AUTOSAR XML (schema 00044)
package /ComponentTypes
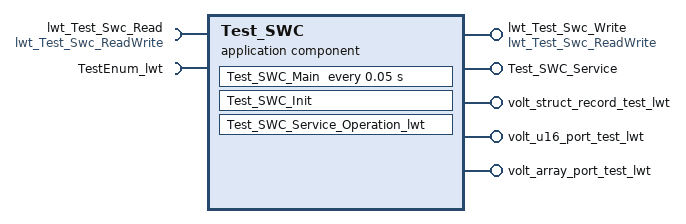
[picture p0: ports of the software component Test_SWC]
  application sw component type Test_SWC
    require port lwt_Test_Swc_Read: nonqueued-receiver-com-spec{data-element=u8_Signal_lwt, init-value=0}, required-interface=lwt_Test_Swc_ReadWrite
    5 x provide port:
      lwt_Test_Swc_Write: nonqueued-sender-com-spec{data-element=u8_Signal_lwt, init-value=0}, provided-interface=lwt_Test_Swc_ReadWrite
      Test_SWC_Service: server-com-spec{operation=Operation_lwt, queue-length=1}, provided-interface=Test_SWC_Service
      volt_struct_record_test_lwt: nonqueued-sender-com-spec{data-element=St_Signal, init-value=fields=[ElementConstant:0, ElementConstant_1:0]}, provided-interface=volt_struct_record_test_lwt
      volt_u16_port_test_lwt: nonqueued-sender-com-spec{data-element=u16_signal, init-value=0}, provided-interface=volt_u16_port_test_lwt
      volt_array_port_test_lwt: nonqueued-sender-com-spec{data-element=u8_signal, init-value=[0]}, provided-interface=volt_array_port_test_lwt
    require port TestEnum_lwt: nonqueued-receiver-com-spec{data-element=u8_signal, init-value=0}, required-interface=TestEnum_lwt
    behavior Test_SWC_InternalBehavior
      timing event TMT_Test_SWC_Main: start-on-event=Test_SWC_Main, period=0.05
      init event Test_SWC_InitEvent: start-on-event=Test_SWC_Init
      operation invoked event OIT_Test_SWC_Service_Operation_lwt_Test_SWC_Service_Operation_lwt: start-on-event=Test_SWC_Service_Operation_lwt, operation=Test_SWC_Service.Operation_lwt
      runnable Test_SWC_Main: minimum-start-interval=0.05
        data-receive-point-by-arguments:
          access REC_lwt_Test_Swc_Read_u8_Signal_lwt: accessed-variable=lwt_Test_Swc_Read.u8_Signal_lwt
          access REC_TestEnum_lwt_u8_signal: accessed-variable=TestEnum_lwt.u8_signal
        data-send-points:
          4 x access:
            SEND_lwt_Test_Swc_Write_u8_Signal_lwt: accessed-variable=lwt_Test_Swc_Write.u8_Signal_lwt
            SEND_volt_struct_record_test_lwt_St_Signal: accessed-variable=volt_struct_record_test_lwt.St_Signal
            SEND_volt_u16_port_test_lwt_u16_signal: accessed-variable=volt_u16_port_test_lwt.u16_signal
            SEND_volt_array_port_test_lwt_u8_signal: accessed-variable=volt_array_port_test_lwt.u8_signal
      runnable Test_SWC_Init
      runnable Test_SWC_Service_Operation_lwt
  swc implementation Test_SWC_Implementation: behavior=Test_SWC_InternalBehavior
